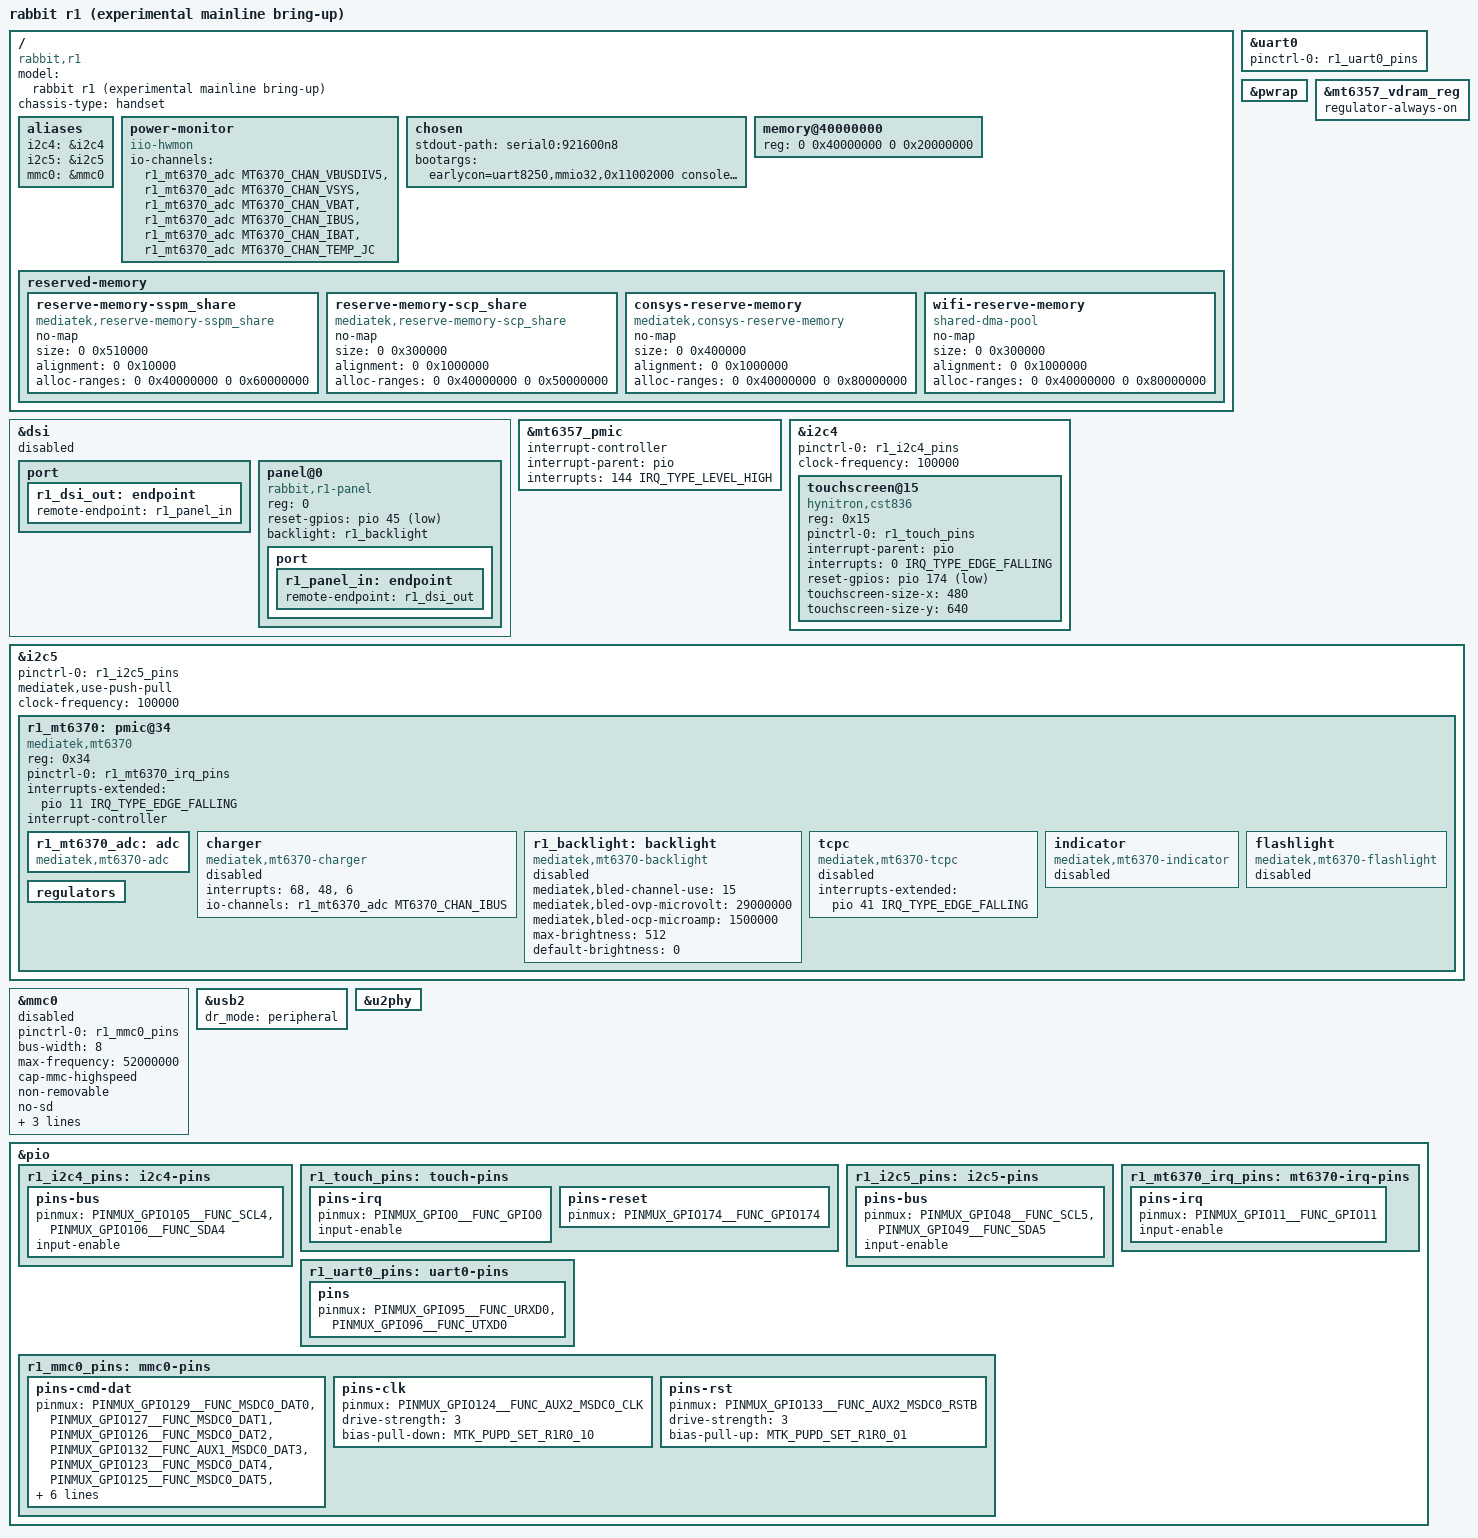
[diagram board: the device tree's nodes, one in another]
// SPDX-License-Identifier: (GPL-2.0-only OR MIT)
/*
 * Experimental rabbit r1 bring-up tree. NOT hardware validated.
 * Board wiring: rabbit-hmi-oss r1 source and RabbitOS v0.8.293 DT/DTBO.
 * Pin groups follow the MT6765 port's Nokia ROO example where the SoC
 * muxes agree with Rabbit's gpio_init_default table.
 *
 * The stock loader must populate actual RAM and firmware carve-outs.
 * The memory entry below is the stock DT's 512 MiB placeholder, NOT an
 * assertion that the device has only 512 MiB. Inspect the live FDT before
 * relying on it. Do not apply the stock vendor overlay to this tree.
 */

/dts-v1/;

#include <dt-bindings/iio/adc/mediatek,mt6370_adc.h>
#include <dt-bindings/pinctrl/mediatek,mt6765-pinfunc.h>
#include "mt6765.dtsi"
#include "mt6357.dtsi"

/ {
	model = "rabbit r1 (experimental mainline bring-up)";
	compatible = "rabbit,r1", "mediatek,mt6765";
	chassis-type = "handset";

	aliases {
		i2c4 = &i2c4;
		i2c5 = &i2c5;
		mmc0 = &mmc0;
	};

	power-monitor {
		compatible = "iio-hwmon";
		io-channels = <&r1_mt6370_adc MT6370_CHAN_VBUSDIV5>,
			      <&r1_mt6370_adc MT6370_CHAN_VSYS>,
			      <&r1_mt6370_adc MT6370_CHAN_VBAT>,
			      <&r1_mt6370_adc MT6370_CHAN_IBUS>,
			      <&r1_mt6370_adc MT6370_CHAN_IBAT>,
			      <&r1_mt6370_adc MT6370_CHAN_TEMP_JC>;
	};

	chosen {
		stdout-path = "serial0:921600n8";
		/* Single CPU until the r1's PSCI/firmware behavior is measured. */
		bootargs = "earlycon=uart8250,mmio32,0x11002000 console=ttyS0,921600n8 maxcpus=1 clk_ignore_unused regulator_ignore_unused";
	};

	/* LK's /memory lookup accepts this unit address and updates the reg. */
	memory@40000000 {
		device_type = "memory";
		reg = <0 0x40000000 0 0x20000000>;
	};

	/* Dynamic reservations copied from the stock base tree. Their final
	 * addresses, plus loader-added TEE/modem reservations, need live-FDT
	 * verification. Remote processors are not enabled by this board file.
	 */
	reserved-memory {
		#address-cells = <2>;
		#size-cells = <2>;
		ranges;

		reserve-memory-sspm_share {
			compatible = "mediatek,reserve-memory-sspm_share";
			no-map;
			size = <0 0x510000>;
			alignment = <0 0x10000>;
			alloc-ranges = <0 0x40000000 0 0x60000000>;
		};

		reserve-memory-scp_share {
			compatible = "mediatek,reserve-memory-scp_share";
			no-map;
			size = <0 0x300000>;
			alignment = <0 0x1000000>;
			alloc-ranges = <0 0x40000000 0 0x50000000>;
		};

		consys-reserve-memory {
			compatible = "mediatek,consys-reserve-memory";
			no-map;
			size = <0 0x400000>;
			alignment = <0 0x1000000>;
			alloc-ranges = <0 0x40000000 0 0x80000000>;
		};

		wifi-reserve-memory {
			compatible = "shared-dma-pool";
			no-map;
			size = <0 0x300000>;
			alignment = <0 0x1000000>;
			alloc-ranges = <0 0x40000000 0 0x80000000>;
		};
	};
};

&uart0 {
	pinctrl-names = "default";
	pinctrl-0 = <&r1_uart0_pins>;
	status = "okay";
};

&pwrap {
	status = "okay";
};

&dsi {
	/* Host timing, PHY and power handoff still need validation. */
	status = "disabled";

	port {
		r1_dsi_out: endpoint {
			remote-endpoint = <&r1_panel_in>;
		};
	};

	panel@0 {
		compatible = "rabbit,r1-panel";
		reg = <0>;
		reset-gpios = <&pio 45 GPIO_ACTIVE_LOW>;
		backlight = <&r1_backlight>;

		port {
			r1_panel_in: endpoint {
				remote-endpoint = <&r1_dsi_out>;
			};
		};
	};
};

&mt6357_pmic {
	interrupt-controller;
	interrupt-parent = <&pio>;
	interrupts = <144 IRQ_TYPE_LEVEL_HIGH>;
	#interrupt-cells = <2>;
};

&mt6357_vdram_reg {
	regulator-always-on;
};

&i2c4 {
	pinctrl-names = "default";
	pinctrl-0 = <&r1_i2c4_pins>;
	clock-frequency = <100000>;
	/* Experimental: stock AP channel and touch wiring, not board-tested. */
	status = "okay";

	touchscreen@15 {
		/* Primary vendor configuration; CST328 variants need another driver. */
		compatible = "hynitron,cst836";
		reg = <0x15>;
		pinctrl-names = "default";
		pinctrl-0 = <&r1_touch_pins>;
		interrupt-parent = <&pio>;
		interrupts = <0 IRQ_TYPE_EDGE_FALLING>;
		reset-gpios = <&pio 174 GPIO_ACTIVE_LOW>;
		touchscreen-size-x = <480>;
		touchscreen-size-y = <640>;
	};
};

&i2c5 {
	pinctrl-names = "default";
	pinctrl-0 = <&r1_i2c5_pins>;
	/* Keep the stock electrical mode, at standard speed for bring-up. */
	mediatek,use-push-pull;
	clock-frequency = <100000>;
	status = "okay";

	r1_mt6370: pmic@34 {
		compatible = "mediatek,mt6370";
		reg = <0x34>;
		pinctrl-names = "default";
		pinctrl-0 = <&r1_mt6370_irq_pins>;
		interrupts-extended = <&pio 11 IRQ_TYPE_EDGE_FALLING>;
		interrupt-controller;
		#interrupt-cells = <1>;

		r1_mt6370_adc: adc {
			compatible = "mediatek,mt6370-adc";
			#io-channel-cells = <1>;
		};

		/* MFD creates absent children too: explicitly gate unfinished ones. */
		charger {
			compatible = "mediatek,mt6370-charger";
			interrupts = <68>, <48>, <6>;
			interrupt-names = "uvp_d_evt", "attach_i", "mivr";
			io-channels = <&r1_mt6370_adc MT6370_CHAN_IBUS>;
			/* Needs battery limits, temperature policy and USB detection. */
			status = "disabled";
		};

		r1_backlight: backlight {
			compatible = "mediatek,mt6370-backlight";
			mediatek,bled-channel-use = /bits/ 8 <15>;
			mediatek,bled-ovp-microvolt = <29000000>;
			mediatek,bled-ocp-microamp = <1500000>;
			max-brightness = <512>;
			default-brightness = <0>;
			/* Keep LK's display state until the panel handoff is ready. */
			status = "disabled";
		};

		tcpc {
			compatible = "mediatek,mt6370-tcpc";
			interrupts-extended = <&pio 41 IRQ_TYPE_EDGE_FALLING>;
			status = "disabled";
		};

		indicator {
			compatible = "mediatek,mt6370-indicator";
			#address-cells = <1>;
			#size-cells = <0>;
			status = "disabled";
		};

		flashlight {
			compatible = "mediatek,mt6370-flashlight";
			#address-cells = <1>;
			#size-cells = <0>;
			status = "disabled";
		};

		/* Register the rails without requesting voltage or enable changes. */
		regulators {
		};
	};
};

&mmc0 {
	pinctrl-names = "default";
	pinctrl-0 = <&r1_mmc0_pins>;
	bus-width = <8>;
	/* Start at legacy/high-speed timing; HS200/HS400 tuning is untested. */
	max-frequency = <52000000>;
	cap-mmc-highspeed;
	non-removable;
	no-sd;
	no-sdio;
	vmmc-supply = <&mt6357_vemc_reg>;
	/* VIO18 is inferred from the SoC reference; verify on the board. */
	vqmmc-supply = <&mt6357_vio18_reg>;
	/* MT6765 port reports partial eMMC support. First boot uses initramfs.
	 * Enable only for an instrumented storage test after PMIC validation.
	 */
	status = "disabled";
};

&usb2 {
	dr_mode = "peripheral";
	status = "okay";
};

&u2phy {
	status = "okay";
};

&pio {
	r1_i2c4_pins: i2c4-pins {
		pins-bus {
			pinmux = <PINMUX_GPIO105__FUNC_SCL4>,
				 <PINMUX_GPIO106__FUNC_SDA4>;
			input-enable;
		};
	};

	r1_touch_pins: touch-pins {
		pins-irq {
			pinmux = <PINMUX_GPIO0__FUNC_GPIO0>;
			input-enable;
		};

		pins-reset {
			pinmux = <PINMUX_GPIO174__FUNC_GPIO174>;
		};
	};

	r1_i2c5_pins: i2c5-pins {
		pins-bus {
			pinmux = <PINMUX_GPIO48__FUNC_SCL5>,
				 <PINMUX_GPIO49__FUNC_SDA5>;
			input-enable;
		};
	};

	r1_mt6370_irq_pins: mt6370-irq-pins {
		pins-irq {
			pinmux = <PINMUX_GPIO11__FUNC_GPIO11>;
			input-enable;
		};
	};

	r1_uart0_pins: uart0-pins {
		pins {
			pinmux = <PINMUX_GPIO95__FUNC_URXD0>,
				 <PINMUX_GPIO96__FUNC_UTXD0>;
		};
	};

	r1_mmc0_pins: mmc0-pins {
		pins-cmd-dat {
			pinmux = <PINMUX_GPIO129__FUNC_MSDC0_DAT0>,
				 <PINMUX_GPIO127__FUNC_MSDC0_DAT1>,
				 <PINMUX_GPIO126__FUNC_MSDC0_DAT2>,
				 <PINMUX_GPIO132__FUNC_AUX1_MSDC0_DAT3>,
				 <PINMUX_GPIO123__FUNC_MSDC0_DAT4>,
				 <PINMUX_GPIO125__FUNC_MSDC0_DAT5>,
				 <PINMUX_GPIO128__FUNC_MSDC0_DAT6>,
				 <PINMUX_GPIO130__FUNC_AUX2_MSDC0_DAT7>,
				 <PINMUX_GPIO122__FUNC_AUX2_MSDC0_CMD>;
			input-enable;
			drive-strength = <3>;
			bias-pull-up = <MTK_PUPD_SET_R1R0_01>;
		};

		pins-clk {
			pinmux = <PINMUX_GPIO124__FUNC_AUX2_MSDC0_CLK>;
			drive-strength = <3>;
			bias-pull-down = <MTK_PUPD_SET_R1R0_10>;
		};

		pins-rst {
			pinmux = <PINMUX_GPIO133__FUNC_AUX2_MSDC0_RSTB>;
			drive-strength = <3>;
			bias-pull-up = <MTK_PUPD_SET_R1R0_01>;
		};
	};
};
